VERSION "1"

NS_ :

BS_:

BU_: Ecu1 Ecu2

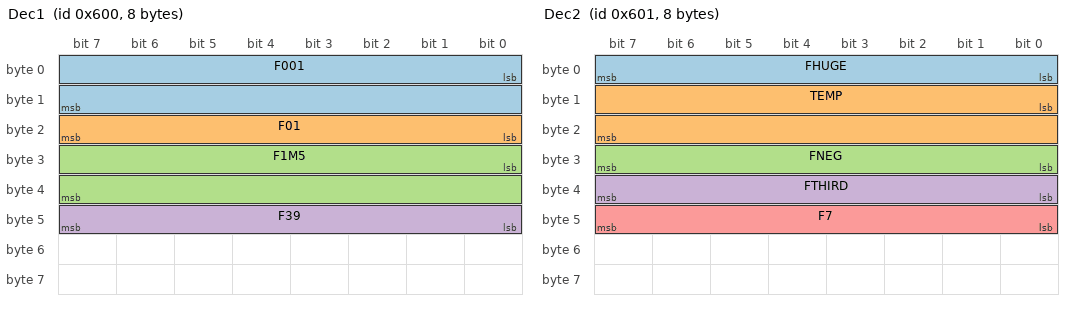
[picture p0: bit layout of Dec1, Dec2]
BO_ 1536 Dec1: 8 Ecu1
 SG_ F001 : 0|16@1+ (0.001,0) [0|65.535] "V" Ecu2
 SG_ F01 : 16|8@1+ (0.1,-40) [-40|-14.5] "degC" Ecu2
 SG_ F1M5 : 24|16@1+ (1e-05,0) [0|0.65535] "A" Ecu2
 SG_ F39 : 40|8@1+ (0.00390625,0) [0|0.99609375] "" Ecu2

BO_ 1537 Dec2: 8 Ecu1
 SG_ FHUGE : 0|8@1+ (1000000000000,0) [0|255000000000000] "" Ecu2
 SG_ TEMP : 8|16@1+ (0.01,-273.15) [-273.15|382.2] "degC" Ecu2
 SG_ FNEG : 24|8@1+ (0.1,-12.8) [-12.8|12.7] "" Ecu2
 SG_ FTHIRD : 32|8@1+ (0.3,0) [0|76.5] "" Ecu2
 SG_ F7 : 40|8@1+ (0.07,0) [0|17.85] "" Ecu2
